# STM32F413 register map
File version: 1.5
CPU: CM4 r0p1, little endian, MPU, FPU, 4 interrupt priority bits
Registers are 32-bit, read-write, reset 0x0 unless marked. A register's access mark holds for its fields unless they carry their own. Offsets are from the block's base; [hi:lo] are bit positions; {n}, {i} and the like mark numbered series; 'fields as' and 'values as' point back to an identical list.

## FSMC — Flexible static memory controller
Base 0x60000000
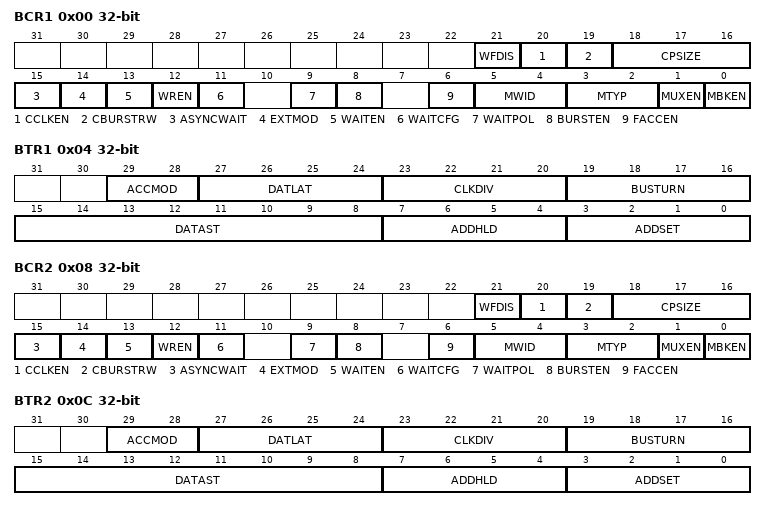
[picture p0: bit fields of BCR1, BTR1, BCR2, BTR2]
0x00 BCR1
  [21] WFDIS — Write FIFO Disable
  [20] CCLKEN — Continuous Clock Enable
  [19] CBURSTRW — Write burst enable
  [18:16] CPSIZE — CRAM page size
  [15] ASYNCWAIT — Wait signal during asynchronous transfers
  [14] EXTMOD — Extended mode enable
  [13] WAITEN — Wait enable bit
  [12] WREN — Write enable bitWREN
  [11] WAITCFG — Wait timing configuration
  [9] WAITPOL — Wait signal polarity bit
  [8] BURSTEN — Burst enable bit
  [6] FACCEN — Flash access enable
  [5:4] MWID — Memory data bus width
  [3:2] MTYP — Memory type
  [1] MUXEN — Memory bank enable bit
  [0] MBKEN — Memory bank enable bit
0x04 BTR1
  [29:28] ACCMOD — Access mode
  [27:24] DATLAT — Data latency
  [23:20] CLKDIV — Clock divide ratio
  [19:16] BUSTURN — Bus turnaround phase duration
  [15:8] DATAST — Data-phase duration
  [7:4] ADDHLD — Address-hold phase duration
  [3:0] ADDSET — Address setup phase duration
0x08 BCR2
  [21] WFDIS — Write FIFO Disable
  [20] CCLKEN — Continuous Clock Enable
  [19] CBURSTRW — Write burst enable
  [18:16] CPSIZE — CRAM page size
  [15] ASYNCWAIT — Wait signal during asynchronous transfers
  [14] EXTMOD — Extended mode enable
  [13] WAITEN — Wait enable bit
  [12] WREN — Write enable bit
  [11] WAITCFG — Wait timing configuration
  [9] WAITPOL — Wait signal polarity bit
  [8] BURSTEN — Burst enable bit
  [6] FACCEN — Flash access enable
  [5:4] MWID — Memory data bus width
  [3:2] MTYP — Memory type
  [1] MUXEN — Address/data multiplexing enable bit
  [0] MBKEN — Memory bank enable bit
0x0C BTR2
  fields as BTR1
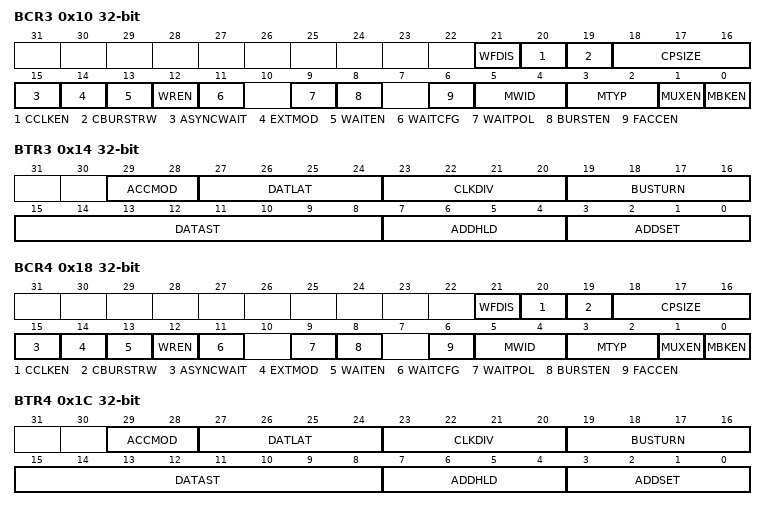
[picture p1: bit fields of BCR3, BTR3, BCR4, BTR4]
0x10 BCR3
  [21] WFDIS — Write FIFO Disable
  [20] CCLKEN — Continuous Clock Enable
  [19] CBURSTRW — Write burst enable
  [18:16] CPSIZE — CRAM page size
  [15] ASYNCWAIT — Wait signal during asynchronous transfers
  [14] EXTMOD — Extended mode enable
  [13] WAITEN — Write enable bit
  [12] WREN — Write enable bit
  [11] WAITCFG — Wait timing configuration
  [9] WAITPOL — Wait signal polarity bit
  [8] BURSTEN — Burst enable bit
  [6] FACCEN — Flash access enable
  [5:4] MWID — Memory data bus width
  [3:2] MTYP — Memory type
  [1] MUXEN — Address/data multiplexing enable bit
  [0] MBKEN — Memory bank enable bit
0x14 BTR3
  fields as BTR1
0x18 BCR4
  [21] WFDIS — Write FIFO Disable
  [20] CCLKEN — Continuous Clock Enable
  [19] CBURSTRW — Write burst enable
  [18:16] CPSIZE — CRAM page size
  [15] ASYNCWAIT — Extended mode enable
  [14] EXTMOD — Extended mode enable
  [13] WAITEN — Wait enable bit
  [12] WREN — Write enable bit
  [11] WAITCFG — Wait timing configuration
  [9] WAITPOL — Wait signal polarity bit
  [8] BURSTEN — Burst enable bit
  [6] FACCEN — Flash access enable
  [5:4] MWID — Memory data bus width
  [3:2] MTYP — Memory type
  [1] MUXEN — Address/data multiplexing enable bit
  [0] MBKEN — Memory bank enable bit
0x1C BTR4
  fields as BTR1
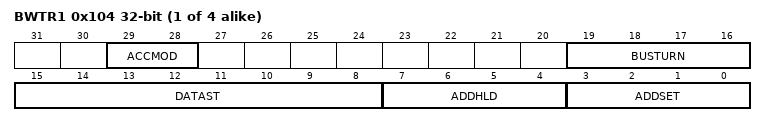
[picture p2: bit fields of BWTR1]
{0xFC+8i} BWTR{i} (i=1..4)
  [29:28] ACCMOD — Access mode
  [19:16] BUSTURN — Bus turnaround phase duration
  [15:8] DATAST — Data-phase duration
  [7:4] ADDHLD — Address-hold phase duration
  [3:0] ADDSET — Address setup phase duration

## ADC_Common — ADC common registers
Base 0x40012300
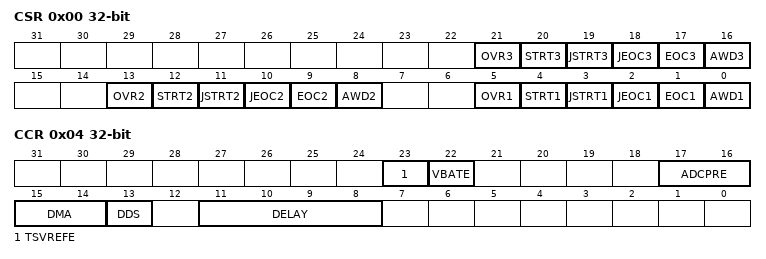
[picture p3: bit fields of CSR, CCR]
0x00 CSR ro — ADC Common status register
  [21] OVR3 — Overrun flag of ADC3
  [20] STRT3 — Regular channel Start flag of ADC 3
  [19] JSTRT3 — Injected channel Start flag of ADC 3
  [18] JEOC3 — Injected channel end of conversion of ADC 3
  [17] EOC3 — End of conversion of ADC 3
  [16] AWD3 — Analog watchdog flag of ADC 3
  [13] OVR2 — Overrun flag of ADC 2
  [12] STRT2 — Regular channel Start flag of ADC 2
  [11] JSTRT2 — Injected channel Start flag of ADC 2
  [10] JEOC2 — Injected channel end of conversion of ADC 2
  [9] EOC2 — End of conversion of ADC 2
  [8] AWD2 — Analog watchdog flag of ADC 2
  [5] OVR1 — Overrun flag of ADC 1
  [4] STRT1 — Regular channel Start flag of ADC 1
  [3] JSTRT1 — Injected channel Start flag of ADC 1
  [2] JEOC1 — Injected channel end of conversion of ADC 1
  [1] EOC1 — End of conversion of ADC 1
  [0] AWD1 — Analog watchdog flag of ADC 1
0x04 CCR — ADC common control register
  [23] TSVREFE — Temperature sensor and VREFINT enable
  [22] VBATE — VBAT enable
  [17:16] ADCPRE — ADC prescaler
  [15:14] DMA — Direct memory access mode for multi ADC mode
  [13] DDS — DMA disable selection for multi-ADC mode
  [11:8] DELAY — Delay between 2 sampling phases

## FPU — Floting point unit
Base 0xE000EF34
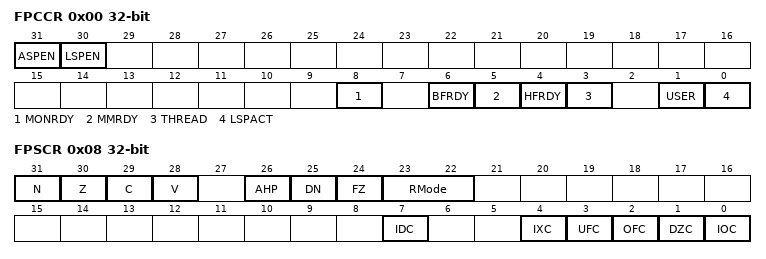
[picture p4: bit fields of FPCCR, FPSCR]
0x00 FPCCR — Floating-point context control register
  [31] ASPEN, [30] LSPEN, [8] MONRDY, [6] BFRDY, [5] MMRDY, [4] HFRDY, [3] THREAD, [1] USER, [0] LSPACT
0x04 FPCAR — Floating-point context address register
  [31:3] ADDRESS — Location of unpopulated floating-point
0x08 FPSCR — Floating-point status control register
  [31] N — Negative condition code flag
  [30] Z — Zero condition code flag
  [29] C — Carry condition code flag
  [28] V — Overflow condition code flag
  [26] AHP — Alternative half-precision control bit
  [25] DN — Default NaN mode control bit
  [24] FZ — Flush-to-zero mode control bit:
  [23:22] RMode — Rounding Mode control field
  [7] IDC — Input denormal cumulative exception bit.
  [4] IXC — Inexact cumulative exception bit
  [3] UFC — Underflow cumulative exception bit
  [2] OFC — Overflow cumulative exception bit
  [1] DZC — Division by zero cumulative exception bit.
  [0] IOC — Invalid operation cumulative exception bit

## MPU — Memory protection unit
Base 0xE000ED90
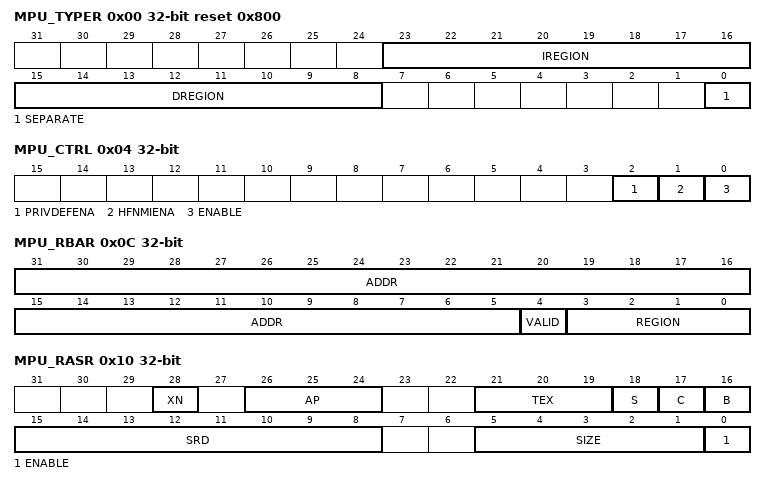
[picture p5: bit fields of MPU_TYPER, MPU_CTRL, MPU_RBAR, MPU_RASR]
0x00 MPU_TYPER ro reset 0x800 — MPU type register
  [23:16] IREGION — Number of MPU instruction regions
  [15:8] DREGION — Number of MPU data regions
  [0] SEPARATE — Separate flag
0x04 MPU_CTRL — MPU control register
  [2] PRIVDEFENA — Enable priviliged software access to default memory map
  [1] HFNMIENA — Enables the operation of MPU during hard fault
  [0] ENABLE — Enables the MPU
0x08 MPU_RNR — MPU region number register
  [7:0] REGION — MPU region
0x0C MPU_RBAR — MPU region base address register
  [31:5] ADDR — Region base address field
  [4] VALID — MPU region number valid
  [3:0] REGION — MPU region field
0x10 MPU_RASR — MPU region attribute and size register
  [28] XN — Instruction access disable bit
  [26:24] AP — Access permission
  [21:19] TEX — memory attribute
  [18] S — Shareable memory attribute
  [17] C — memory attribute
  [16] B — memory attribute
  [15:8] SRD — Subregion disable bits
  [5:1] SIZE — Size of the MPU protection region
  [0] ENABLE — Region enable bit.

## STK — SysTick timer
Base 0xE000E010
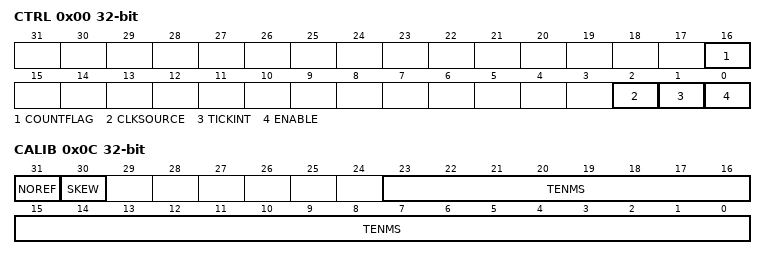
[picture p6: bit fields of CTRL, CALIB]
0x00 CTRL — SysTick control and status register
  [16] COUNTFLAG
  [2] CLKSOURCE — Clock source selection
  [1] TICKINT — SysTick exception request enable
  [0] ENABLE — Counter enable
0x04 LOAD — SysTick reload value register
  [23:0] RELOAD — RELOAD value
0x08 VAL — SysTick current value register
  [23:0] CURRENT — Current counter value
0x0C CALIB — SysTick calibration value register
  [31] NOREF — NOREF flag. Reads as zero
  [30] SKEW — SKEW flag: Indicates whether the TENMS value is exact
  [23:0] TENMS — Calibration value

## NVIC_STIR — Nested vectored interrupt controller
Base 0xE000EF00
0x00 STIR — Software trigger interrupt register
  [8:0] INTID — Software generated interrupt ID

## FPU_CPACR — Floating point unit CPACR
Base 0xE000ED88
0x00 CPACR — Coprocessor access control register
  [23:20] CP

## SCB_ACTRL — System control block ACTLR
Base 0xE000E008
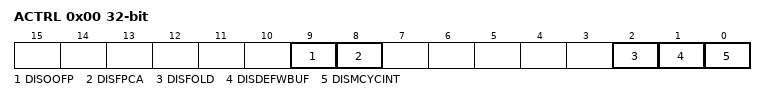
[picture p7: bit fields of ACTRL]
0x00 ACTRL — Auxiliary control register
  [9] DISOOFP, [8] DISFPCA, [2] DISFOLD, [1] DISDEFWBUF, [0] DISMCYCINT
